# FM33FG0XXA register map
File version: 1.0
CPU: SC000 r1p0, little endian, MPU, no FPU, 3 interrupt priority bits
Registers are 32-bit, read-only, reset 0x0 unless marked. A register's access mark holds for its fields unless they carry their own. Offsets are from the block's base; [hi:lo] are bit positions; {n}, {i} and the like mark numbered series.

## GPIO — GPIO module information
Base 0x40000E40
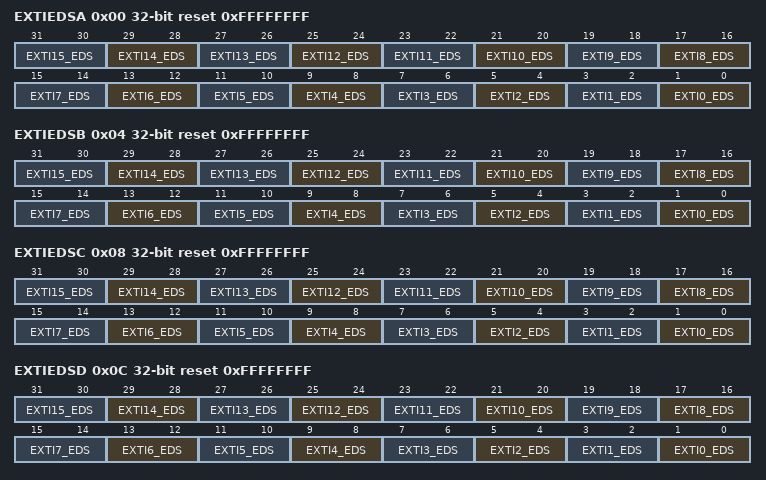
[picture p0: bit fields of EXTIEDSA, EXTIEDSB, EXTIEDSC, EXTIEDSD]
0x00 EXTIEDSA rw reset 0xFFFFFFFF — External Interrupt Edge Select and Enable RegisterA
  [2n+1:2n] EXTI{n}_EDS (n=0..15) — EXTI{n}_EDS field description
0x04 EXTIEDSB rw reset 0xFFFFFFFF — External Interrupt Edge Select and Enable RegisterB
  [2n+1:2n] EXTI{n}_EDS (n=0..15) — EXTI{n}_EDS field description
0x08 EXTIEDSC rw reset 0xFFFFFFFF — External Interrupt Edge Select and Enable RegisterC
  [2n+1:2n] EXTI{n}_EDS (n=0..15) — EXTI{n}_EDS field description
0x0C EXTIEDSD rw reset 0xFFFFFFFF — External Interrupt Edge Select and Enable RegisterD
  [2n+1:2n] EXTI{n}_EDS (n=0..15) — EXTI{n}_EDS field description
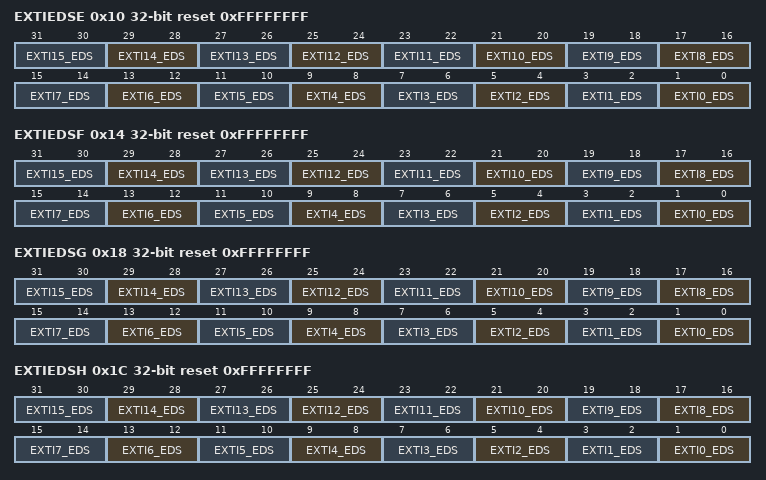
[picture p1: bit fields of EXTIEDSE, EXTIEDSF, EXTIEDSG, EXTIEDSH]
0x10 EXTIEDSE rw reset 0xFFFFFFFF — External Interrupt Edge Select and Enable RegisterE
  [2n+1:2n] EXTI{n}_EDS (n=0..15) — EXTI{n}_EDS field description
0x14 EXTIEDSF rw reset 0xFFFFFFFF — External Interrupt Edge Select and Enable RegisterF
  [2n+1:2n] EXTI{n}_EDS (n=0..15) — EXTI{n}_EDS field description
0x18 EXTIEDSG rw reset 0xFFFFFFFF — External Interrupt Edge Select and Enable RegisterG
  [2n+1:2n] EXTI{n}_EDS (n=0..15) — EXTI{n}_EDS field description
0x1C EXTIEDSH rw reset 0xFFFFFFFF — External Interrupt Edge Select and Enable RegisterH
  [2n+1:2n] EXTI{n}_EDS (n=0..15) — EXTI{n}_EDS field description
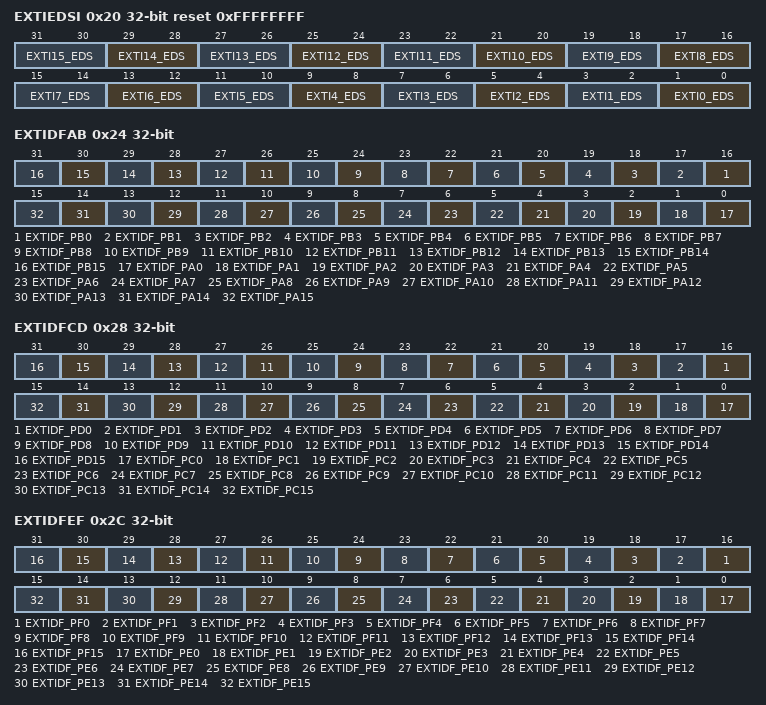
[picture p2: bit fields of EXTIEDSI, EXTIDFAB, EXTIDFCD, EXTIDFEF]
0x20 EXTIEDSI rw reset 0xFFFFFFFF — External Interrupt Edge Select and Enable RegisterI
  [2n+1:2n] EXTI{n}_EDS (n=0..15) — EXTI{n}_EDS field description
0x24 EXTIDFAB rw — External Interrupt Digital Filter Register AB
  [n+16] EXTIDF_PB{n} (n=0..15) — EXTIDF_PB{n} field description
  [n] EXTIDF_PA{n} (n=0..15) — EXTIDF_PA{n} field description
0x28 EXTIDFCD rw — External Interrupt Digital Filter Register CD
  [n+16] EXTIDF_PD{n} (n=0..15) — EXTIDF_PD{n} field description
  [n] EXTIDF_PC{n} (n=0..15) — EXTIDF_PC{n} field description
0x2C EXTIDFEF rw — External Interrupt Digital Filter Register EF
  [n+16] EXTIDF_PF{n} (n=0..15) — EXTIDF_PF{n} field description
  [n] EXTIDF_PE{n} (n=0..15) — EXTIDF_PE{n} field description
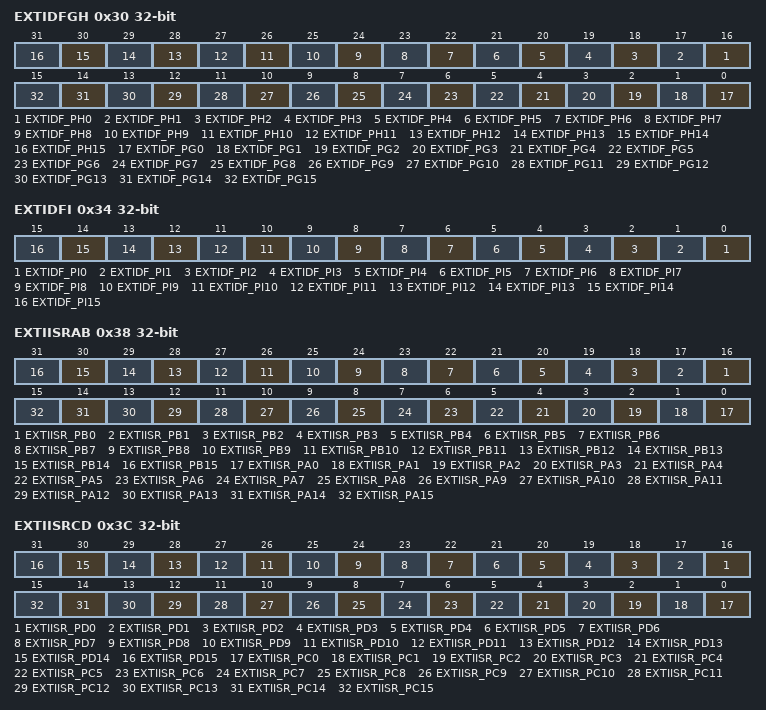
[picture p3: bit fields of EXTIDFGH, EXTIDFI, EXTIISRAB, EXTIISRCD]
0x30 EXTIDFGH rw — External Interrupt Digital Filter Register GH
  [n+16] EXTIDF_PH{n} (n=0..15) — EXTIDF_PH{n} field description
  [n] EXTIDF_PG{n} (n=0..15) — EXTIDF_PG{n} field description
0x34 EXTIDFI rw — External Interrupt Digital Filter Register I
  [n] EXTIDF_PI{n} (n=0..15) — EXTIDF_PI{n} field description
0x38 EXTIISRAB rw — External Interrupt and Status Register AB
  [n+16] EXTIISR_PB{n} (n=0..15) — EXTIISR_PB{n} field description
  [n] EXTIISR_PA{n} (n=0..15) — EXTIISR_PA{n} field description
0x3C EXTIISRCD rw — External Interrupt and Status Register CD
  [n+16] EXTIISR_PD{n} (n=0..15) — EXTIISR_PD{n} field description
  [n] EXTIISR_PC{n} (n=0..15) — EXTIISR_PC{n} field description
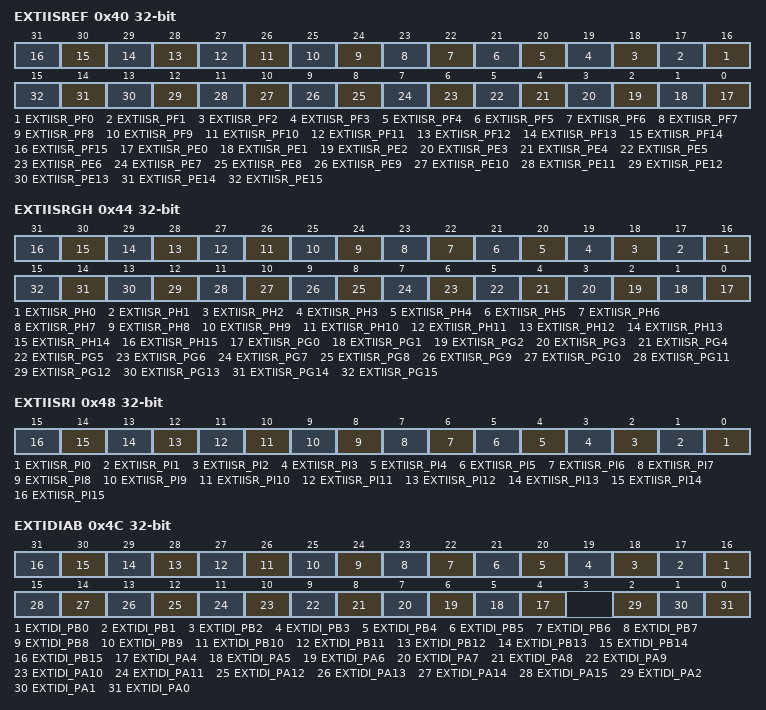
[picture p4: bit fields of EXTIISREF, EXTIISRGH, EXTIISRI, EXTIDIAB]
0x40 EXTIISREF rw — External Interrupt and Status Register EF
  [n+16] EXTIISR_PF{n} (n=0..15) — EXTIISR_PF{n} field description
  [n] EXTIISR_PE{n} (n=0..15) — EXTIISR_PE{n} field description
0x44 EXTIISRGH rw — External Interrupt and Status Register GH
  [n+16] EXTIISR_PH{n} (n=0..15) — EXTIISR_PH{n} field description
  [n] EXTIISR_PG{n} (n=0..15) — EXTIISR_PG{n} field description
0x48 EXTIISRI rw — External Interrupt and Status Register I
  [n] EXTIISR_PI{n} (n=0..15) — EXTIISR_PI{n} field description
0x4C EXTIDIAB — External Interrupt Data Input Register AB
  [n+16] EXTIDI_PB{n} (n=0..15) — EXTIDI_PB{n} field description
  [n] EXTIDI_PA{n} (n=4..15) — EXTIDI_PA{n} field description
  [2] EXTIDI_PA2 — EXTIDI_PA2 field description
  [1] EXTIDI_PA1 — EXTIDI_PA1 field description
  [0] EXTIDI_PA0 — EXTIDI_PA0 field description
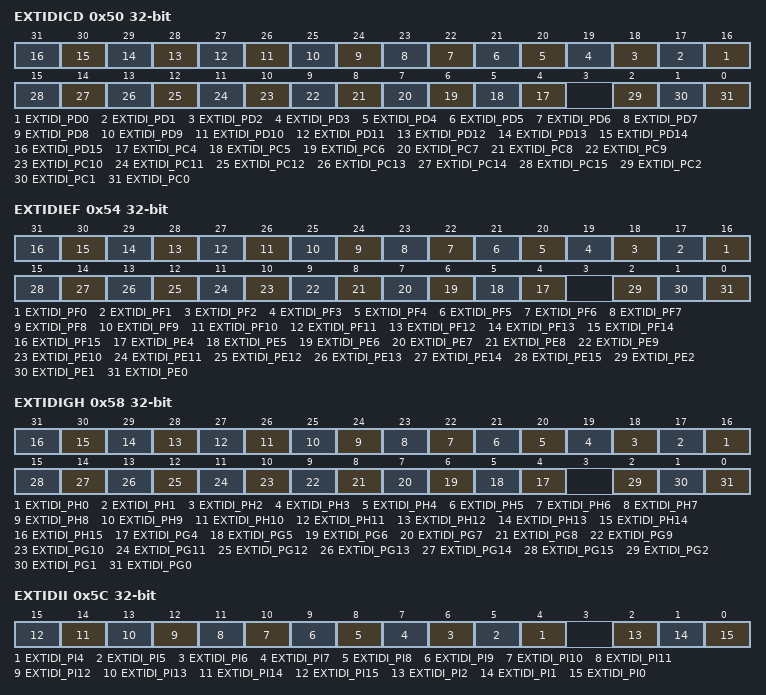
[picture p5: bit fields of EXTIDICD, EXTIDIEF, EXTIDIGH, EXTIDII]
0x50 EXTIDICD — External Interrupt Data Input Register CD
  [n+16] EXTIDI_PD{n} (n=0..15) — EXTIDI_PD{n} field description
  [n] EXTIDI_PC{n} (n=4..15) — EXTIDI_PC{n} field description
  [2] EXTIDI_PC2 — EXTIDI_PC2 field description
  [1] EXTIDI_PC1 — EXTIDI_PC1 field description
  [0] EXTIDI_PC0 — EXTIDI_PC0 field description
0x54 EXTIDIEF — External Interrupt Data Input Register EF
  [n+16] EXTIDI_PF{n} (n=0..15) — EXTIDI_PF{n} field description
  [n] EXTIDI_PE{n} (n=4..15) — EXTIDI_PE{n} field description
  [2] EXTIDI_PE2 — EXTIDI_PE2 field description
  [1] EXTIDI_PE1 — EXTIDI_PE1 field description
  [0] EXTIDI_PE0 — EXTIDI_PE0 field description
0x58 EXTIDIGH — External Interrupt Data Input Register GH
  [n+16] EXTIDI_PH{n} (n=0..15) — EXTIDI_PH{n} field description
  [n] EXTIDI_PG{n} (n=4..15) — EXTIDI_PG{n} field description
  [2] EXTIDI_PG2 — EXTIDI_PG2 field description
  [1] EXTIDI_PG1 — EXTIDI_PG1 field description
  [0] EXTIDI_PG0 — EXTIDI_PG0 field description
0x5C EXTIDII — External Interrupt Data Input Register I
  [n] EXTIDI_PI{n} (n=4..15) — EXTIDI_PI{n} field description
  [2] EXTIDI_PI2 — EXTIDI_PI2 field description
  [1] EXTIDI_PI1 — EXTIDI_PI1 field description
  [0] EXTIDI_PI0 — EXTIDI_PI0 field description
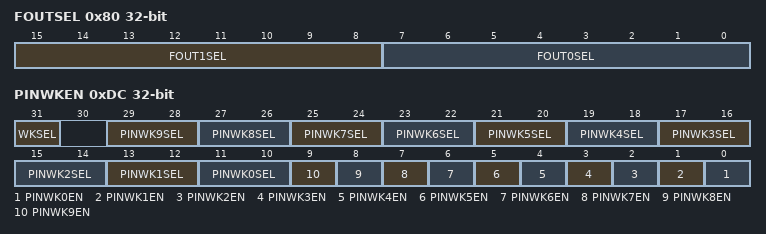
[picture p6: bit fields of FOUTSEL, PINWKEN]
0x80 FOUTSEL rw — Frequency Output Select Register
  [15:8] FOUT1SEL — FOUT1SEL field description
  [7:0] FOUT0SEL — FOUT0SEL field description
0xDC PINWKEN rw — Wakeup Enable Register
  [31] WKSEL — WKSEL field description
  [2n+11:2n+10] PINWK{n}SEL (n=0..9) — PINWK{n}SEL field description
  [n] PINWK{n}EN (n=0..9) — PINWK{n}EN field description
